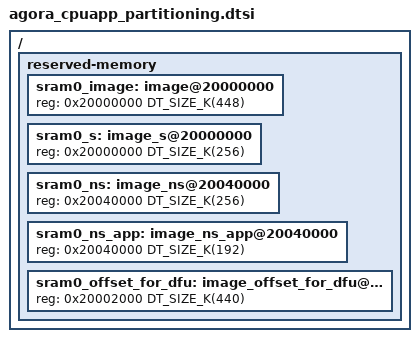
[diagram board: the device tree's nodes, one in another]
/*
 * Default Flash planning for Application MCU.
 *
 * Zephyr build for nRF5340 with ARM TrustZone-M support, implies building
 * Secure and Non-Secure Zephyr images.
 *
 * Secure image will be placed, by default, in flash0 (or in slot0, if MCUboot
 * is present). Secure image will use sram0 for system memory.
 *
 * Non-Secure image will be placed in slot0_ns, and use sram0_ns for system
 * memory.
 *
 * Note that the Secure image only requires knowledge of the beginning of the
 * Non-Secure image (not its size).
 */

/* Default SRAM planning when building for nRF5340 with ARM TrustZone-M support
 * - Lowest 256 kB SRAM allocated to Secure image (sram0_s)
 * - Middle 192 kB allocated to Non-Secure image (sram0_ns)
 * - Upper 64 kB SRAM allocated as Shared memory (sram0_shared)
 *   (see {board}_shared_sram.dtsi)
 */
/ {
	reserved-memory {
		#address-cells = <1>;
		#size-cells = <1>;
		ranges;

		/* Zephyr image(s) memory */
		sram0_image: image@20000000 {
			reg = <0x20000000 DT_SIZE_K(448)>;
		};

		/* Secure image memory */
		sram0_s: image_s@20000000 {
			reg = <0x20000000 DT_SIZE_K(256)>;
		};

		/* Non-Secure image memory */
		sram0_ns: image_ns@20040000 {
			reg = <0x20040000 DT_SIZE_K(256)>;
		};

		/* Non-Secure image memory */
		sram0_ns_app: image_ns_app@20040000 {

			reg = <0x20040000 DT_SIZE_K(192)>;
		};

		/* Used by MCUboot when SB_CONFIG_MCUBOOT_NRF53_MULTI_IMAGE_UPDATE is enabled, so the
		 * RAM-backed netcore staging buffer doesn't collide with MCUboot's
		 * own RAM usage. See nrf/modules/mcuboot/flash_sim.overlay.
		 */
		sram0_offset_for_dfu: image_offset_for_dfu@20002000 {
			reg = <0x20002000 DT_SIZE_K(440)>;
		};
	};
};
